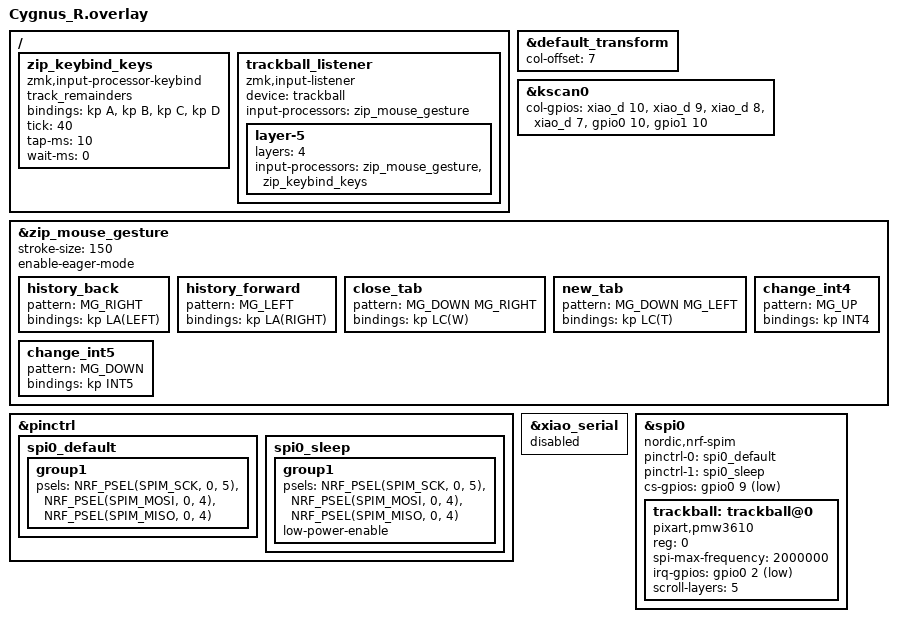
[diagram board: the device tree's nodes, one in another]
#include "Cygnus.dtsi"
#include <input/processors.dtsi>
#include <mouse-gesture.dtsi>
#include <input/processors/zmk-input-processor-keybind.dtsi>
#include <dt-bindings/zmk/keys.h>
#include <dt-bindings/zmk/modifiers.h>

/* あなたの環境の実測値に基づく独自定義 gestuer_mouse用 */
#define MG_UP    1
#define MG_DOWN  2
#define MG_RIGHT 8
#define MG_LEFT  4


&default_transform {
    col-offset = <7>;
};

&kscan0 {
    col-gpios
        = <&xiao_d 10 GPIO_ACTIVE_HIGH>
        , <&xiao_d 9 GPIO_ACTIVE_HIGH>
        , <&xiao_d 8 GPIO_ACTIVE_HIGH>
        , <&xiao_d 7 GPIO_ACTIVE_HIGH>
        , <&gpio0 10 GPIO_ACTIVE_HIGH>
        , <&gpio1 10 GPIO_ACTIVE_HIGH>
        ;
};

/ {
    /* プロセッサ本体の定義はそのまま */
    zip_keybind_keys: zip_keybind_keys {
        compatible = "zmk,input-processor-keybind";
        #input-processor-cells = <0>; 
        track_remainders;
        bindings = <&kp A &kp B &kp C &kp D>;
        tick = <40>;
        tap-ms = <10>;
        wait-ms = <0>;
    };

    /* リスナーを「レイヤー条件付き」に書き換えます */
    trackball_listener: trackball_listener {
        compatible = "zmk,input-listener";
        device = <&trackball>;
        status = "okay";

        /* 通常時はジェスチャーのみ（常時発動を防止） */
        input-processors = <&zip_mouse_gesture>;

        /* 特定のレイヤー（例：5番）にいる時だけプロセッサを追加適用する */
        layer-5 {
            layers = <4>;
            input-processors = <&zip_mouse_gesture>, <&zip_keybind_keys>;
        };
    };
};


&zip_mouse_gesture {
    status = "okay";
    stroke-size = <150>; 
    enable-eager-mode;

    history_back {
        pattern = <MG_RIGHT>;
        bindings = <&kp LA(LEFT)>;
    };

    history_forward {
        pattern = <MG_LEFT>;
        bindings = <&kp LA(RIGHT)>;
    };

    close_tab {
        pattern = <MG_DOWN MG_RIGHT>;
        bindings = <&kp LC(W)>;
    };

    new_tab {
        pattern = <MG_DOWN MG_LEFT>;
        bindings = <&kp LC(T)>;
    };
    change_int4 {
        pattern = <MG_UP>;
        bindings = <&kp INT4>;
    };
    change_int5 {
        pattern = <MG_DOWN>;
        bindings = <&kp INT5>;
    };
};




&pinctrl {
    spi0_default: spi0_default {
        group1 {
            psels = <NRF_PSEL(SPIM_SCK, 0, 5)>,
                <NRF_PSEL(SPIM_MOSI, 0, 4)>,
                <NRF_PSEL(SPIM_MISO, 0, 4)>;
        };
    };

    spi0_sleep: spi0_sleep {
        group1 {
            psels = <NRF_PSEL(SPIM_SCK, 0, 5)>,
                <NRF_PSEL(SPIM_MOSI, 0, 4)>,
                <NRF_PSEL(SPIM_MISO, 0, 4)>;
            low-power-enable;
        };
    };
};

&xiao_serial { status = "disabled"; };

&spi0 {
    status = "okay";
    compatible = "nordic,nrf-spim";
    pinctrl-0 = <&spi0_default>;
    pinctrl-1 = <&spi0_sleep>;
    pinctrl-names = "default", "sleep";
    cs-gpios = <&gpio0 9 GPIO_ACTIVE_LOW>;

    trackball: trackball@0 {
        status = "okay";
        compatible = "pixart,pmw3610";
        reg = <0>;
        spi-max-frequency = <2000000>;
        irq-gpios = <&gpio0 2 17>;
        scroll-layers = <5>;
    };
};
